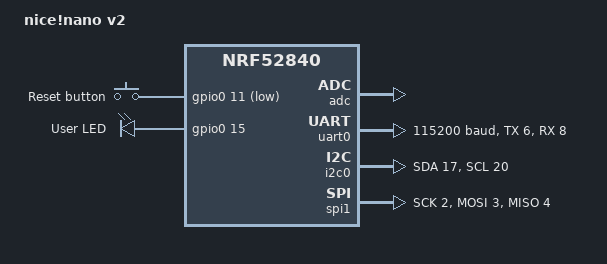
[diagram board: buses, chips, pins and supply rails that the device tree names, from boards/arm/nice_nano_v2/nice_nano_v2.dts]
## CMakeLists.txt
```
cmake_minimum_required(VERSION 3.20.0)
find_package(Zephyr REQUIRED HINTS $ENV{ZEPHYR_BASE})
project(ble_fixture)

target_sources(app PRIVATE src/main.c)
```

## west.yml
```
manifest:
  remotes:
    - name: zmkfirmware
      url-base: https://github.com/zmkfirmware
  projects:
    - name: zmk
      remote: zmkfirmware
      revision: v0.3.0  # 使用 ZMK v0.3.0
      # 移除 import: true，避免导入 west.yml
  self:
    path: .
```

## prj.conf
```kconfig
CONFIG_BT=y
CONFIG_BT_PERIPHERAL=y
CONFIG_BT_BROADCASTER=y
CONFIG_BT_OBSERVER=n
CONFIG_BT_CENTRAL=n
CONFIG_BT_DEVICE_NAME="Nordic_Blinky"
CONFIG_BT_DEVICE_APPEARANCE=0
CONFIG_BT_MAX_CONN=2
CONFIG_BT_SETTINGS=n
CONFIG_SETTINGS=n
CONFIG_BT_PRIVACY=n
CONFIG_BT_CTLR_TX_PWR_PLUS_8=y

CONFIG_GPIO=y
CONFIG_PRINTK=y
CONFIG_BOOT_BANNER=y
CONFIG_LOG=y
CONFIG_CONSOLE=y
CONFIG_SERIAL=y
CONFIG_UART_CONSOLE=y
CONFIG_UART_LINE_CTRL=y
CONFIG_USB_DEVICE_STACK=y
CONFIG_USB_CDC_ACM=y
CONFIG_USB_DEVICE_INITIALIZE_AT_BOOT=y
CONFIG_USB_DEVICE_PRODUCT="Nordic_Blinky"

CONFIG_MAIN_STACK_SIZE=2048
CONFIG_SYSTEM_WORKQUEUE_STACK_SIZE=2048
CONFIG_USE_DT_CODE_PARTITION=y
CONFIG_BUILD_OUTPUT_UF2=y
CONFIG_BUILD_OUTPUT_HEX=y
```

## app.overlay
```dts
/ {
    aliases {
        led0 = &blue_led;
    };

    chosen {
        zephyr,console = &cdc_acm_uart0;
        zephyr,shell-uart = &cdc_acm_uart0;
    };
};

&zephyr_udc0 {
    cdc_acm_uart0: cdc_acm_uart0 {
        compatible = "zephyr,cdc-acm-uart";
    };
};
```

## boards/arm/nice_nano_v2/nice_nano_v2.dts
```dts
/dts-v1/;
#include <nordic/nrf52840_qiaa.dtsi>

/ {
    model = "nice!nano v2";
    compatible = "nice,nano-v2";

    chosen {
        zephyr,console = &uart0;
        zephyr,shell-uart = &uart0;
        zephyr,uart-mcumgr = &uart0;
        zephyr,bt-mon-uart = &uart0;
        zephyr,bt-c2h-uart = &uart0;
        zephyr,sram = &sram0;
        zephyr,flash = &flash0;
        zephyr,code-partition = &slot0_partition;
    };

    /* Buttons */
    buttons {
        compatible = "gpio-keys";
        button0: button_0 {
            gpios = <&gpio0 11 GPIO_ACTIVE_LOW>;
            label = "Reset button";
        };
    };

    /* LEDs */
    leds {
        compatible = "gpio-leds";
        led0: led_0 {
            gpios = <&gpio0 15 GPIO_ACTIVE_HIGH>;
            label = "User LED";
        };
    };
};

&adc {
    status = "okay";
};

&gpiote {
    status = "okay";
};

&gpio0 {
    status = "okay";
};

&gpio1 {
    status = "okay";
};

&uart0 {
    compatible = "nordic,nrf-uart";
    status = "okay";
    current-speed = <115200>;
    tx-pin = <6>;
    rx-pin = <8>;
};

&i2c0 {
    status = "okay";
    sda-pin = <17>;
    scl-pin = <20>;
};

&spi1 {
    status = "okay";
    sck-pin = <2>;
    mosi-pin = <3>;
    miso-pin = <4>;
};

&flash0 {
    partitions {
        compatible = "fixed-partitions";
        #address-cells = <1>;
        #size-cells = <1>;

        boot_partition: partition@0 {
            label = "mcuboot";
            reg = <0x00000000 0x0000C000>;
        };
        slot0_partition: partition@c000 {
            label = "image-0";
            reg = <0x0000C000 0x00067000>;
        };
        slot1_partition: partition@73000 {
            label = "image-1";
            reg = <0x00073000 0x00067000>;
        };
        storage_partition: partition@da000 {
            label = "storage";
            reg = <0x000da000 0x00026000>;
        };
    };
};
```

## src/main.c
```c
#include <zephyr/kernel.h>
#include <zephyr/device.h>
#include <zephyr/drivers/gpio.h>
#include <zephyr/sys/printk.h>
#include <zephyr/sys/util.h>
#include <zephyr/bluetooth/bluetooth.h>
#include <zephyr/bluetooth/conn.h>
#include <zephyr/bluetooth/gatt.h>
#include <zephyr/bluetooth/hci.h>
#include <zephyr/bluetooth/uuid.h>

/* Nordic Blinky / LED Button Service (LBS) */
#define BT_UUID_LBS_VAL \
	BT_UUID_128_ENCODE(0x00001523, 0x1212, 0xefde, 0x1523, 0x785feabcd123)
#define BT_UUID_LBS_BUTTON_VAL \
	BT_UUID_128_ENCODE(0x00001524, 0x1212, 0xefde, 0x1523, 0x785feabcd123)
#define BT_UUID_LBS_LED_VAL \
	BT_UUID_128_ENCODE(0x00001525, 0x1212, 0xefde, 0x1523, 0x785feabcd123)

static const struct bt_uuid_128 lbs_uuid = BT_UUID_INIT_128(BT_UUID_LBS_VAL);
static const struct bt_uuid_128 lbs_button_uuid = BT_UUID_INIT_128(BT_UUID_LBS_BUTTON_VAL);
static const struct bt_uuid_128 lbs_led_uuid = BT_UUID_INIT_128(BT_UUID_LBS_LED_VAL);

#define DEVICE_NAME     CONFIG_BT_DEVICE_NAME
#define DEVICE_NAME_LEN (sizeof(DEVICE_NAME) - 1)

static const struct gpio_dt_spec led = GPIO_DT_SPEC_GET_OR(DT_ALIAS(led0), gpios, {0});
static bool led_ready;
static uint8_t led_state;
static uint8_t button_state;
static volatile bool connected;
static volatile bool advertising;

/*
 * Primary ADV must be self-contained for passive scanners / factory fixtures.
 * Flags (3) + complete name "Nordic_Blinky" (16) = 19 bytes (< 31).
 * 128-bit LBS UUID goes in the scan response for nRF Connect / active scan.
 */
static const struct bt_data ad[] = {
	BT_DATA_BYTES(BT_DATA_FLAGS, (BT_LE_AD_GENERAL | BT_LE_AD_NO_BREDR)),
	BT_DATA(BT_DATA_NAME_COMPLETE, DEVICE_NAME, DEVICE_NAME_LEN),
};

static const struct bt_data sd[] = {
	BT_DATA_BYTES(BT_DATA_UUID128_ALL, BT_UUID_LBS_VAL),
};

/* ~20–30 ms connectable undirected legacy advertising */
#define FIXTURE_ADV_PARAM \
	BT_LE_ADV_PARAM(BT_LE_ADV_OPT_CONNECTABLE, \
			BT_GAP_ADV_FAST_INT_MIN_1, \
			BT_GAP_ADV_FAST_INT_MAX_1, \
			NULL)

static void apply_led(uint8_t on)
{
	led_state = on ? 1 : 0;
	if (led_ready) {
		gpio_pin_set_dt(&led, led_state);
	}
}

static ssize_t read_button(struct bt_conn *conn, const struct bt_gatt_attr *attr,
			   void *buf, uint16_t len, uint16_t offset)
{
	return bt_gatt_attr_read(conn, attr, buf, len, offset, &button_state,
				 sizeof(button_state));
}

static ssize_t read_led(struct bt_conn *conn, const struct bt_gatt_attr *attr,
			void *buf, uint16_t len, uint16_t offset)
{
	return bt_gatt_attr_read(conn, attr, buf, len, offset, &led_state, sizeof(led_state));
}

static ssize_t write_led(struct bt_conn *conn, const struct bt_gatt_attr *attr,
			 const void *buf, uint16_t len, uint16_t offset, uint8_t flags)
{
	uint8_t value;

	if (offset != 0 || len != 1) {
		return BT_GATT_ERR(BT_ATT_ERR_INVALID_ATTRIBUTE_LEN);
	}

	value = ((const uint8_t *)buf)[0];
	apply_led(value);
	printk("LBS LED write -> %u\n", led_state);
	return len;
}

static void button_ccc_changed(const struct bt_gatt_attr *attr, uint16_t value)
{
	printk("LBS button CCC %s\n", value ? "notify on" : "notify off");
}

BT_GATT_SERVICE_DEFINE(lbs_svc,
	BT_GATT_PRIMARY_SERVICE(&lbs_uuid),
	BT_GATT_CHARACTERISTIC(&lbs_button_uuid.uuid,
			       BT_GATT_CHRC_READ | BT_GATT_CHRC_NOTIFY,
			       BT_GATT_PERM_READ, read_button, NULL, NULL),
	BT_GATT_CCC(button_ccc_changed, BT_GATT_PERM_READ | BT_GATT_PERM_WRITE),
	BT_GATT_CHARACTERISTIC(&lbs_led_uuid.uuid,
			       BT_GATT_CHRC_READ | BT_GATT_CHRC_WRITE,
			       BT_GATT_PERM_READ | BT_GATT_PERM_WRITE,
			       read_led, write_led, NULL),
);

static void start_adv(void)
{
	int err;

	if (connected) {
		return;
	}

	err = bt_le_adv_start(FIXTURE_ADV_PARAM, ad, ARRAY_SIZE(ad), sd, ARRAY_SIZE(sd));
	if (err == -EALREADY) {
		advertising = true;
		return;
	}
	if (err) {
		advertising = false;
		printk("Advertising FAILED (%d)\n", err);
	} else {
		advertising = true;
		printk("Advertising as '%s' (name in ADV, LBS UUID in SR)\n", DEVICE_NAME);
	}
}

static void connected_cb(struct bt_conn *conn, uint8_t err)
{
	char addr[BT_ADDR_LE_STR_LEN];

	bt_addr_le_to_str(bt_conn_get_dst(conn), addr, sizeof(addr));
	if (err) {
		printk("Connect failed %s (err %u)\n", addr, err);
		connected = false;
		advertising = false;
		start_adv();
		return;
	}
	connected = true;
	advertising = false;
	printk("Connected %s\n", addr);
}

static void disconnected_cb(struct bt_conn *conn, uint8_t reason)
{
	char addr[BT_ADDR_LE_STR_LEN];

	bt_addr_le_to_str(bt_conn_get_dst(conn), addr, sizeof(addr));
	connected = false;
	advertising = false;
	printk("Disconnected %s (reason 0x%02x)\n", addr, reason);
	start_adv();
}

BT_CONN_CB_DEFINE(conn_cbs) = {
	.connected = connected_cb,
	.disconnected = disconnected_cb,
};

static int init_led(void)
{
	if (!gpio_is_ready_dt(&led)) {
		printk("LED GPIO not ready (firmware still runs)\n");
		return -ENODEV;
	}
	if (gpio_pin_configure_dt(&led, GPIO_OUTPUT_INACTIVE) != 0) {
		printk("LED configure failed\n");
		return -EIO;
	}
	led_ready = true;
	printk("LED ready — blinks while advertising\n");
	return 0;
}

int main(void)
{
	int err;

	printk("\n=== BLE fixture / Nordic_Blinky ===\n");
	printk("Board: nice!nano  build: %s %s\n", __DATE__, __TIME__);

	init_led();

	err = bt_enable(NULL);
	if (err) {
		printk("bt_enable FAILED (%d) — check USB log / LED pattern\n", err);
	} else {
		printk("Bluetooth ready\n");
		start_adv();
	}

	uint32_t tick = 0;
	while (1) {
		tick++;
		if (!connected && led_ready) {
			/* 1 Hz heartbeat: firmware is alive and advertising */
			gpio_pin_toggle_dt(&led);
		}
		if (!connected && !advertising) {
			start_adv();
		}
		if ((tick % 4) == 0) {
			printk("up %us  connected=%d  adv=%d  name=%s  led=%u\n",
			       tick / 2, connected, advertising, DEVICE_NAME, led_state);
		}
		k_sleep(K_MSEC(500));
	}

	return 0;
}
```
